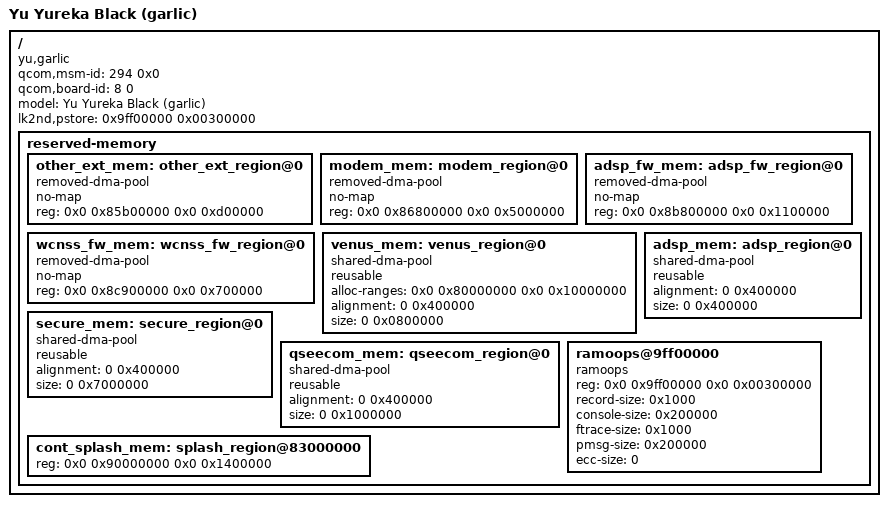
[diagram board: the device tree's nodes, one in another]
// SPDX-License-Identifier: GPL-2.0-only

/dts-v1/;

/include/ "msm8953.dtsi"

/ {
	// This is used by the bootloader to find the correct DTB 
	qcom,msm-id = <294 0x0>;
	qcom,board-id= <8 0>;

	model = "Yu Yureka Black (garlic)";
	compatible = "yu,garlic", "qcom,msm8937", "qcom,msm8937-mtp", "lk2nd,device";
	lk2nd,pstore = <0x9ff00000 0x00300000>;


	// Bootloader won't continue if it can't delete some nodes from below
//	soc {
//		#address-cells = <1>;
//		#size-cells = <1>;
//		ranges = <0x0 0x0 0x0 0xffffffff>;
//	};

	reserved-memory {
		#address-cells = <2>;
		#size-cells = <2>;
		ranges;

		other_ext_mem: other_ext_region@0 {
			compatible = "removed-dma-pool";
			no-map;
			reg = <0x0 0x85b00000 0x0 0xd00000>;
		};

		modem_mem: modem_region@0 {
			compatible = "removed-dma-pool";
			no-map;
			reg = <0x0 0x86800000 0x0 0x5000000>;
		};

		adsp_fw_mem: adsp_fw_region@0 {
			compatible = "removed-dma-pool";
			no-map;
			reg = <0x0 0x8b800000 0x0 0x1100000>;
		};

		wcnss_fw_mem: wcnss_fw_region@0 {
			compatible = "removed-dma-pool";
			no-map;
			reg = <0x0 0x8c900000 0x0 0x700000>;
		};


		venus_mem: venus_region@0 {
			compatible = "shared-dma-pool";
			reusable;
			alloc-ranges = <0x0 0x80000000 0x0 0x10000000>;
			alignment = <0 0x400000>;
			size = <0 0x0800000>;
		};

		secure_mem: secure_region@0 {
			compatible = "shared-dma-pool";
			reusable;
			alignment = <0 0x400000>;
			size = <0 0x7000000>;
		};

		qseecom_mem: qseecom_region@0 {
			compatible = "shared-dma-pool";
			reusable;
			alignment = <0 0x400000>;
			size = <0 0x1000000>;
		};

		adsp_mem: adsp_region@0 {
			compatible = "shared-dma-pool";
			reusable;
			alignment = <0 0x400000>;
			size = <0 0x400000>;
		};

		cont_splash_mem: splash_region@83000000 {
			reg = <0x0 0x90000000 0x0 0x1400000>;

		};

		ramoops@9ff00000 {
			compatible = "ramoops";
			reg = <0x0 0x9ff00000 0x0 0x00300000>;
			record-size = <0x1000>;
			console-size = <0x200000>;
			ftrace-size = <0x1000>;
			pmsg-size = <0x200000>;
			ecc-size = <0>;
		};
	};
};
